# f29h85x_hsm_trng_regs register map
Vendor: Texas Instruments
Peripheral module from a debugger description file (folder HSM).
Registers are 32-bit, read-write, no defined reset value unless marked. A register's access mark holds for its fields unless they carry their own. Offsets are as the file gives them; lines under a group give offsets from that group; [hi:lo] are bit positions; {n}, {i} and the like mark numbered series; 'fields as' and 'values as' point back to an identical list; <NAME> marks a mode.

## HSM_TRNG — HSM TRNG Registers
0x00 TRNG_INPUT_0 — Data input LSW
0x00 TRNG_OUTPUT_0 ro — Data output LSW
0x04 TRNG_INPUT_1 — Data input
0x04 TRNG_OUTPUT_1 ro — Data output
0x08 TRNG_INPUT_2 — Data input
0x08 TRNG_OUTPUT_2 ro — Data output
0x0C TRNG_INPUT_3 — Data input MSW
0x0C TRNG_OUTPUT_3 ro — Data output MSW
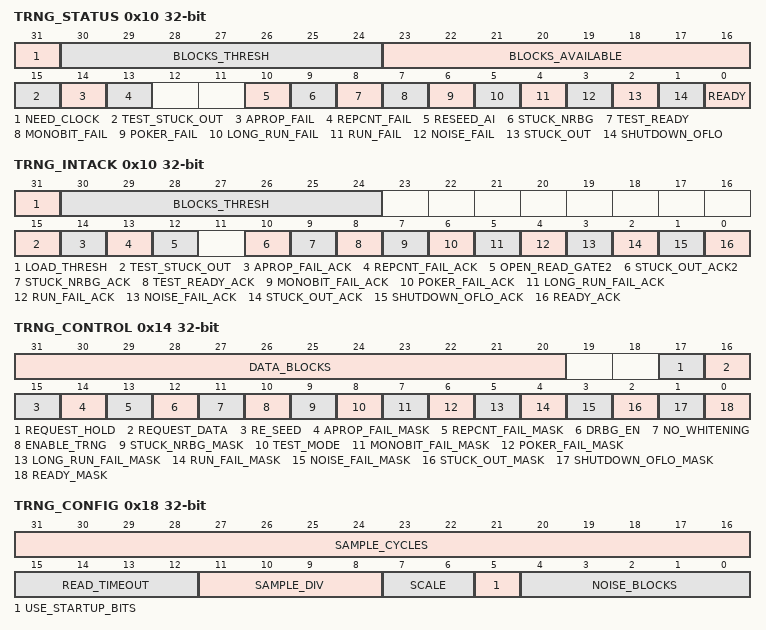
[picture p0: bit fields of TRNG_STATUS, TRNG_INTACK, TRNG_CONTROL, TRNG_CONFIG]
0x10 TRNG_STATUS ro — status register
  [31] NEED_CLOCK, [30:24] BLOCKS_THRESH, [23:16] BLOCKS_AVAILABLE, [15] TEST_STUCK_OUT, [14] APROP_FAIL, [13] REPCNT_FAIL, [10] RESEED_AI, [9] STUCK_NRBG, [8] TEST_READY, [7] MONOBIT_FAIL, [6] POKER_FAIL, [5] LONG_RUN_FAIL, [4] RUN_FAIL, [3] NOISE_FAIL, [2] STUCK_OUT, [1] SHUTDOWN_OFLO, [0] READY
0x10 TRNG_INTACK_SECURE_MODE — TRNG Interrupt Acknowledge Register
  [14:0] READY
0x10 TRNG_INTACK — TRNG Interrupt Acknowledge Register
  [31] LOAD_THRESH, [30:24] BLOCKS_THRESH, [15] TEST_STUCK_OUT, [14] APROP_FAIL_ACK, [13] REPCNT_FAIL_ACK, [12] OPEN_READ_GATE2, [10] STUCK_OUT_ACK2, [9] STUCK_NRBG_ACK, [8] TEST_READY_ACK, [7] MONOBIT_FAIL_ACK, [6] POKER_FAIL_ACK, [5] LONG_RUN_FAIL_ACK, [4] RUN_FAIL_ACK, [3] NOISE_FAIL_ACK, [2] STUCK_OUT_ACK, [1] SHUTDOWN_OFLO_ACK, [0] READY_ACK
0x14 TRNG_CONTROL access per field
  [31:20] DATA_BLOCKS rw, [17] REQUEST_HOLD rw, [16] REQUEST_DATA rw, [15] RE_SEED rw, [14] APROP_FAIL_MASK rw, [13] REPCNT_FAIL_MASK rw, [12] DRBG_EN rw, [11] NO_WHITENING rw, [10] ENABLE_TRNG rw, [9] STUCK_NRBG_MASK rw, [8] TEST_MODE rw, [7] MONOBIT_FAIL_MASK rw, [6] POKER_FAIL_MASK rw, [5] LONG_RUN_FAIL_MASK rw, [4] RUN_FAIL_MASK rw, [3] NOISE_FAIL_MASK rw, [2] STUCK_OUT_MASK rw, [1] SHUTDOWN_OFLO_MASK rw, [0] READY_MASK rw
0x18 TRNG_CONFIG — TRNG Configuration register
  [31:16] SAMPLE_CYCLES, [15:12] READ_TIMEOUT, [11:8] SAMPLE_DIV, [7:6] SCALE, [5] USE_STARTUP_BITS, [4:0] NOISE_BLOCKS
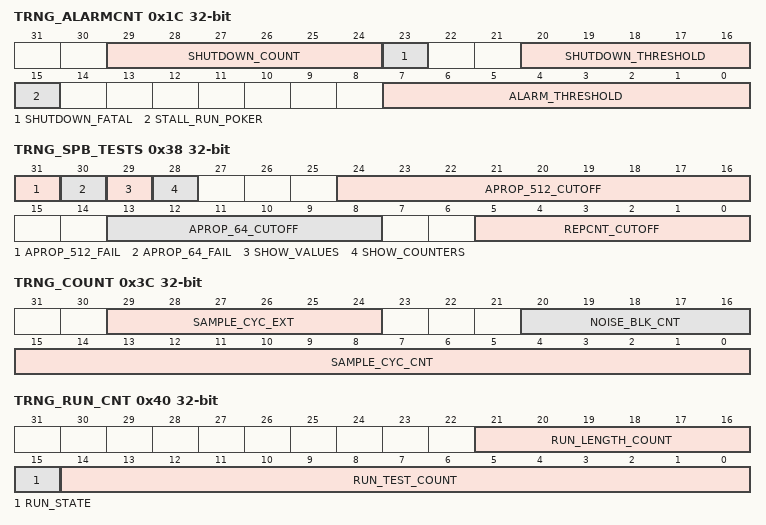
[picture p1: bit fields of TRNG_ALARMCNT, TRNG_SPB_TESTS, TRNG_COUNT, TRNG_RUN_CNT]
0x1C TRNG_ALARMCNT access per field — TRNG Alarm Count Register
  [29:24] SHUTDOWN_COUNT ro, [23] SHUTDOWN_FATAL rw, [20:16] SHUTDOWN_THRESHOLD rw, [15] STALL_RUN_POKER rw, [7:0] ALARM_THRESHOLD rw
0x20 TRNG_FROENABLE
  [7:0] TRNG_FROENABLE
0x24 TRNG_FRODETUNE
  [7:0] TRNG_FRODETUNE
0x28 TRNG_ALARMMASK
  [7:0] TRNG_ALARMMASK
0x2C TRNG_ALARMSTOP
  [7:0] TRNG_ALARMSTOP
0x30 TRNG_RAW_L — Main Shift Register Access Registers
0x34 TRNG_RAW_H — Main Shift Register Access Registers
0x38 TRNG_SPB_TESTS access per field — TRNG Tests Control/Status RegisteR
  [31] APROP_512_FAIL rw, [30] APROP_64_FAIL rw, [29] SHOW_VALUES rw, [28] SHOW_COUNTERS rw, [24:16] APROP_512_CUTOFF rw, [13:8] APROP_64_CUTOFF rw, [5:0] REPCNT_CUTOFF rw
0x3C TRNG_COUNT ro — TRNG Counter Access Register
  [29:24] SAMPLE_CYC_EXT, [20:16] NOISE_BLK_CNT, [15:0] SAMPLE_CYC_CNT
{0x40+4i} TRNG_PS_AI_{i} (i=0..11) — DRBG Vector Registers
  [31:0] VECTOR
0x40 TRNG_RUN_CNT ro — Bits and runs counter states Register
  [21:16] RUN_LENGTH_COUNT, [15] RUN_STATE, [14:0] RUN_TEST_COUNT
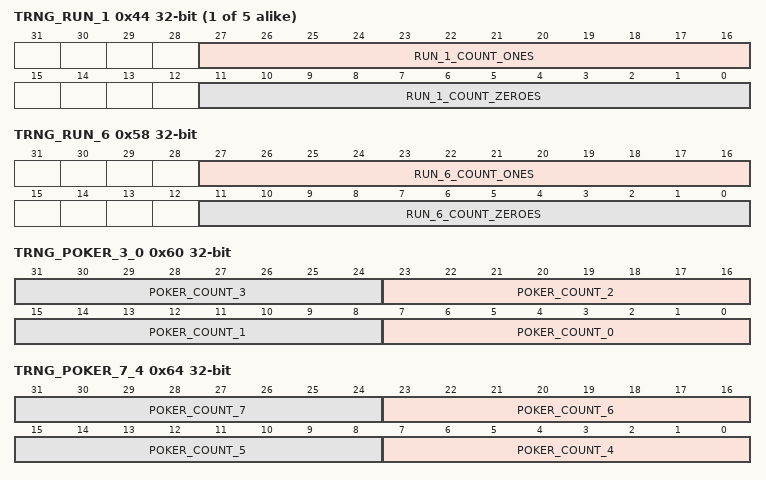
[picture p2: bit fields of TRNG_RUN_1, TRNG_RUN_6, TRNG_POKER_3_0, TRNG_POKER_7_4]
{0x40+4i} TRNG_RUN_{i} ro (i=1..5) — Counters for {i}-bit 0/1 runs Register
  [27:16] RUN_{i}_COUNT_ONES, [11:0] RUN_{i}_COUNT_ZEROES
0x58 TRNG_RUN_6 ro — Counters for 4-bit 0/1 runs Register
  [27:16] RUN_6_COUNT_ONES, [11:0] RUN_6_COUNT_ZEROES
0x5C TRNG_MONOBITCNT ro — Monobit Test Register
  [15:0] MONOBIT_COUNT
0x60 TRNG_POKER_3_0 ro — Poker Test Register
  [8n+7:8n] POKER_COUNT_{n} (n=0..3)
0x64 TRNG_POKER_7_4 ro — Poker Test Register
  [8n-25:8n-32] POKER_COUNT_{n} (n=4..7)
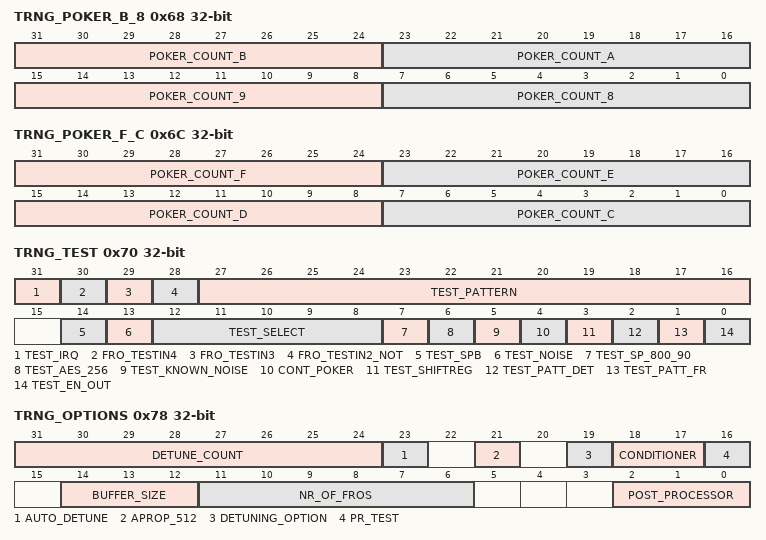
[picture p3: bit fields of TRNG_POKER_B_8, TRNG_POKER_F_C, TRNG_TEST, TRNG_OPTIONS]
0x68 TRNG_POKER_B_8 ro — Poker Test Register
  [31:24] POKER_COUNT_B, [23:16] POKER_COUNT_A, [15:8] POKER_COUNT_9, [7:0] POKER_COUNT_8
0x6C TRNG_POKER_F_C ro — Poker Test Register
  [31:24] POKER_COUNT_F, [23:16] POKER_COUNT_E, [15:8] POKER_COUNT_D, [7:0] POKER_COUNT_C
0x70 TRNG_TEST access per field
  [31] TEST_IRQ rw, [30] FRO_TESTIN4 rw, [29] FRO_TESTIN3 rw, [28] FRO_TESTIN2_NOT rw, [27:16] TEST_PATTERN rw, [14] TEST_SPB rw, [13] TEST_NOISE rw, [12:8] TEST_SELECT rw, [7] TEST_SP_800_90 rw, [6] TEST_AES_256 rw, [5] TEST_KNOWN_NOISE rw, [4] CONT_POKER rw, [3] TEST_SHIFTREG rw, [2] TEST_PATT_DET rw, [1] TEST_PATT_FR rw, [0] TEST_EN_OUT rw
0x74 TRNG_BLOCKCNT access per field — TRNG Block Count Register
  [31:4] BLOCK_COUNT rw
0x78 TRNG_OPTIONS access per field — TRNG HW Options Register
  [31:24] DETUNE_COUNT rw, [23] AUTO_DETUNE rw, [21] APROP_512 ro, [19] DETUNING_OPTION ro, [18:17] CONDITIONER ro, [16] PR_TEST ro, [14:12] BUFFER_SIZE ro, [11:6] NR_OF_FROS ro, [2:0] POST_PROCESSOR ro
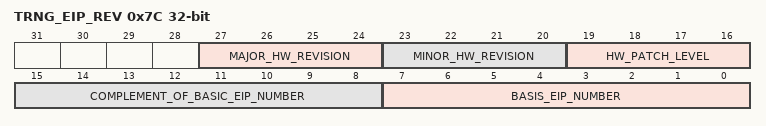
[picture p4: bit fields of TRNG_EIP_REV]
0x7C TRNG_EIP_REV ro — TRNG EIP HW Rev
  [27:24] MAJOR_HW_REVISION, [23:20] MINOR_HW_REVISION, [19:16] HW_PATCH_LEVEL, [15:8] COMPLEMENT_OF_BASIC_EIP_NUMBER, [7:0] BASIS_EIP_NUMBER
